VERSION ""

NS_ :

BS_:

BU_: Vector__XXX

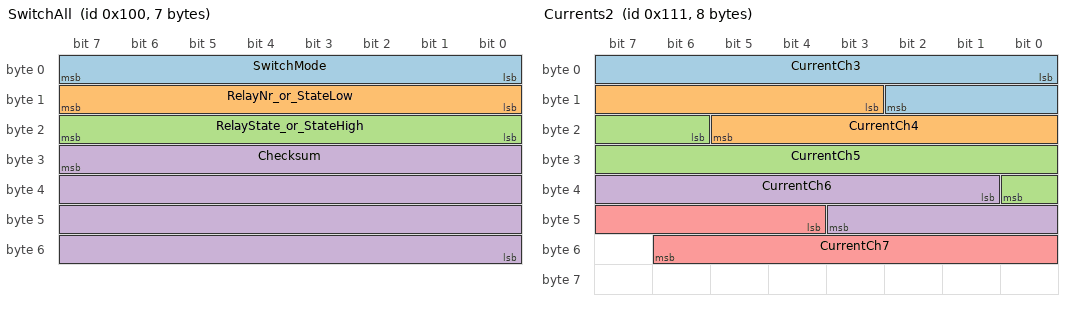
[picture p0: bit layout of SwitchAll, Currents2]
BO_ 256 SwitchAll: 7 Vector__XXX
SG_ SwitchMode : 0|8@1+ (1,0) [0|255] "" Vector__XXX
SG_ RelayNr_or_StateLow : 8|8@1+ (1,0) [0|255] "" Vector__XXX
SG_ RelayState_or_StateHigh : 16|8@1+ (1,0) [0|255] "" Vector__XXX
SG_ Checksum : 31|32@0+ (1,0) [0|4294967295] "" Vector__XXX

BO_ 272 State_Currents: 8 Vector__XXX
SG_ CurrentCh1 : 42|11@1+ (0.01,0) [0|20.47] "" Vector__XXX
SG_ CurrentCh2 : 53|11@1+ (0.01,0) [0|20.47] "" Vector__XXX
SG_ RelayState1 : 0|1@1+ (1,0) [0|1] "" Vector__XXX
SG_ RelayState2 : 1|1@1+ (1,0) [0|1] "" Vector__XXX
SG_ RelayState5 : 4|1@1+ (1,0) [0|1] "" Vector__XXX
SG_ RelayState6 : 5|1@1+ (1,0) [0|1] "" Vector__XXX
SG_ RelayState7 : 6|1@1+ (1,0) [0|1] "" Vector__XXX
SG_ RelayState8 : 7|1@1+ (1,0) [0|1] "" Vector__XXX
SG_ RelayState9 : 8|1@1+ (1,0) [0|1] "" Vector__XXX
SG_ RelayState10 : 9|1@1+ (1,0) [0|1] "" Vector__XXX
SG_ RelayState11 : 10|1@1+ (1,0) [0|1] "" Vector__XXX
SG_ RelayState12 : 11|1@1+ (1,0) [0|1] "" Vector__XXX
SG_ RelayState3 : 2|1@1+ (1,0) [0|1] "" Vector__XXX
SG_ RelayState4 : 3|1@1+ (1,0) [0|1] "" Vector__XXX
SG_ Temperature : 33|9@1+ (0.5,-50) [-50|205.5] "" Vector__XXX
SG_ CurrentErrorCh1 : 12|1@1+ (1,0) [0|1] "" Vector__XXX
SG_ CurrentErrorCh2 : 13|1@1+ (1,0) [0|1] "" Vector__XXX
SG_ CurrentErrorCh3 : 14|1@1+ (1,0) [0|1] "" Vector__XXX
SG_ CurrentErrorCh4 : 15|1@1+ (1,0) [0|1] "" Vector__XXX
SG_ CurrentErrorCh5 : 16|1@1+ (1,0) [0|1] "" Vector__XXX
SG_ CurrentErrorCh6 : 17|1@1+ (1,0) [0|1] "" Vector__XXX
SG_ CurrentErrorCh7 : 18|1@1+ (1,0) [0|1] "" Vector__XXX
SG_ CurrentErrorCh8 : 19|1@1+ (1,0) [0|1] "" Vector__XXX
SG_ CurrentErrorCh9 : 20|1@1+ (1,0) [0|1] "" Vector__XXX
SG_ CurrentErrorCh11 : 22|1@1+ (1,0) [0|1] "" Vector__XXX
SG_ CurrentErrorCh10 : 21|1@1+ (1,0) [0|1] "" Vector__XXX
SG_ CurrentErrorCh12 : 23|1@1+ (1,0) [0|1] "" Vector__XXX

BO_ 273 Currents2: 8 Vector__XXX
SG_ CurrentCh3 : 0|11@1+ (0.01,0) [0|20.47] "" Vector__XXX
SG_ CurrentCh4 : 11|11@1+ (0.01,0) [0|20.47] "" Vector__XXX
SG_ CurrentCh5 : 22|11@1+ (0.01,0) [0|20.47] "" Vector__XXX
SG_ CurrentCh6 : 33|11@1+ (0.01,0) [0|20.47] "" Vector__XXX
SG_ CurrentCh7 : 44|11@1+ (0.01,0) [0|20.47] "" Vector__XXX

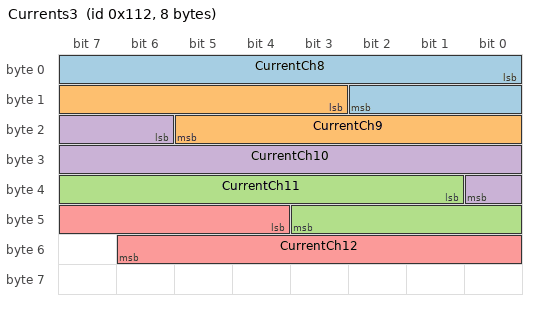
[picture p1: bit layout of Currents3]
BO_ 274 Currents3: 8 Vector__XXX
SG_ CurrentCh8 : 0|11@1+ (0.01,0) [0|20.47] "" Vector__XXX
SG_ CurrentCh9 : 11|11@1+ (0.01,0) [0|20.47] "" Vector__XXX
SG_ CurrentCh11 : 33|11@1+ (0.01,0) [0|20.47] "" Vector__XXX
SG_ CurrentCh10 : 22|11@1+ (0.01,0) [0|20.47] "" Vector__XXX
SG_ CurrentCh12 : 44|11@1+ (0.01,0) [0|20.47] "" Vector__XXX

CM_ SG_ 256 Checksum "CRC32 MPEG2";

BA_DEF_  "BusType" STRING ;

BA_DEF_DEF_  "BusType" "CAN";
